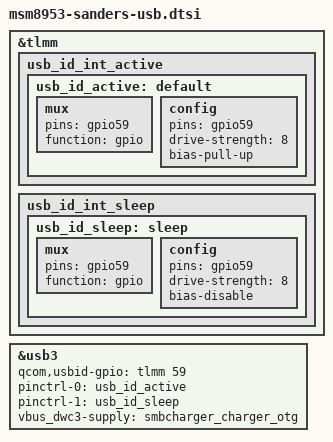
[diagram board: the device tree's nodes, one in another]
&tlmm {
	usb_id_int_active {
		usb_id_active: default {
			mux {
				pins = "gpio59";
				function = "gpio";
			};
			config {
				pins = "gpio59";
				drive-strength = <8>;
				bias-pull-up;
			};
		};
	};
	usb_id_int_sleep {
		usb_id_sleep: sleep {
			mux {
				pins = "gpio59";
				function = "gpio";
			};
			config {
				pins = "gpio59";
				drive-strength = <8>;
				bias-disable;
			};
		};
	};
};

&usb3 {
	qcom,usbid-gpio = <&tlmm 59 0>;
	pinctrl-names = "usbid_default","usbid_sleep";
	pinctrl-0 = <&usb_id_active>;
	pinctrl-1 = <&usb_id_sleep>;
	vbus_dwc3-supply = <&smbcharger_charger_otg>;
};
